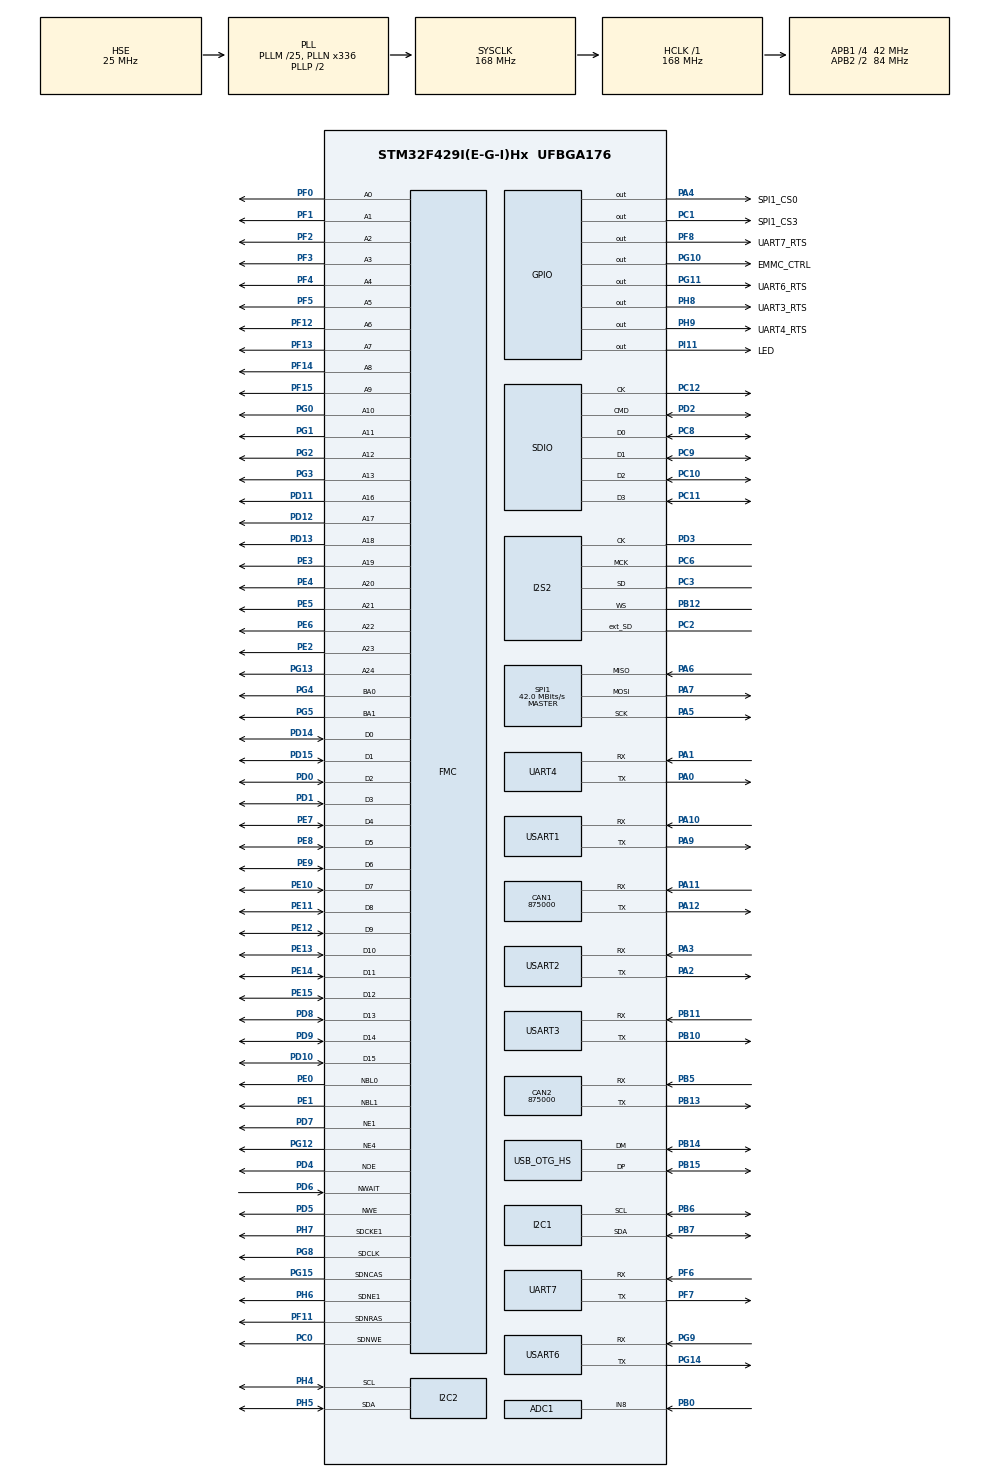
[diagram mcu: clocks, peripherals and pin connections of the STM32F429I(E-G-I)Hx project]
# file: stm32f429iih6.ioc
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ADC1.Channel-0\#ChannelRegularConversion=ADC_CHANNEL_TEMPSENSOR
ADC1.NbrOfConversionFlag=1
ADC1.Rank-0\#ChannelRegularConversion=1
ADC1.SamplingTime-0\#ChannelRegularConversion=ADC_SAMPLETIME_3CYCLES
ADC1.ScanConvMode=DISABLE
ADC1.master=1
CAN1.CalculateBaudRate=875000
CAN1.CalculateTimeBit=1142
CAN1.CalculateTimeQuantum=380.95238095238096
CAN2.CalculateBaudRate=875000
CAN2.CalculateTimeBit=1142
CAN2.CalculateTimeQuantum=380.95238095238096
DMA2D.ColorMode=DMA2D_OUTPUT_RGB565
I2S2.ErrorAudioFreq=0.0 %
I2S2.FullDuplexMode=I2S_FULLDUPLEXMODE_ENABLE
I2S2.Instance=SPI$Index
I2S2.RealAudioFreq=8.0 KHz
I2S2.VirtualMode=I2S_MODE_MASTER
Mcu.Family=STM32F4
Mcu.Name=STM32F429I(E-G-I)Hx
Mcu.Package=UFBGA176
NVIC.PriorityGroup=NVIC_PRIORITYGROUP_4
PA0/WKUP.Mode=Asynchronous
PA0/WKUP.Signal=UART4_TX
PA1.Mode=Asynchronous
PA1.Signal=UART4_RX
PA10.Mode=Asynchronous
PA10.Signal=USART1_RX
PA11.Mode=CAN_Activate
PA11.Signal=CAN1_RX
PA12.Mode=CAN_Activate
PA12.Signal=CAN1_TX
PA13.Mode=Serial_Wire
PA13.Signal=SYS_JTMS-SWDIO
PA14.Mode=Serial_Wire
PA14.Signal=SYS_JTCK-SWCLK
PA2.Mode=Asynchronous
PA2.Signal=USART2_TX
PA3.Mode=Asynchronous
PA3.Signal=USART2_RX
PA4.GPIO_Label=SPI1_CS0
PA4.GPIO_Speed=GPIO_SPEED_FREQ_VERY_HIGH
PA4.Signal=GPIO_Output
PA5.Mode=Full_Duplex_Master
PA5.Signal=SPI1_SCK
PA6.Mode=Full_Duplex_Master
PA6.Signal=SPI1_MISO
PA7.Mode=Full_Duplex_Master
PA7.Signal=SPI1_MOSI
PA9.Mode=Asynchronous
PA9.Signal=USART1_TX
PB0.Signal=ADCx_IN8
PB10.Mode=Asynchronous
PB10.Signal=USART3_TX
PB11.Mode=Asynchronous
PB11.Signal=USART3_RX
PB12.GPIO_Speed=GPIO_SPEED_FREQ_VERY_HIGH
PB12.Mode=Full_Duplex_Master
PB12.Signal=I2S2_WS
PB13.Mode=CAN_Activate
PB13.Signal=CAN2_TX
PB14.Mode=Host_FS
PB14.Signal=USB_OTG_HS_DM
PB15.Mode=Host_FS
PB15.Signal=USB_OTG_HS_DP
PB5.Mode=CAN_Activate
PB5.Signal=CAN2_RX
PB6.GPIO_Pu=GPIO_PULLUP
PB6.Mode=I2C
PB6.Signal=I2C1_SCL
PB7.GPIO_Pu=GPIO_PULLUP
PB7.Mode=I2C
PB7.Signal=I2C1_SDA
PC0.Signal=FMC_SDNWE
PC1.GPIO_Label=SPI1_CS3
PC1.GPIO_Speed=GPIO_SPEED_FREQ_VERY_HIGH
PC1.Signal=GPIO_Output
PC10.GPIO_PuPd=GPIO_PULLUP
PC10.Mode=mmc_4_bits_Wide_bus
PC10.Signal=SDIO_D2
PC11.GPIO_PuPd=GPIO_PULLUP
PC11.Mode=mmc_4_bits_Wide_bus
PC11.Signal=SDIO_D3
PC12.Mode=mmc_4_bits_Wide_bus
PC12.Signal=SDIO_CK
PC2.GPIO_Speed=GPIO_SPEED_FREQ_VERY_HIGH
PC2.Mode=Full_Duplex_Master
PC2.Signal=I2S2_ext_SD
PC3.GPIO_Speed=GPIO_SPEED_FREQ_VERY_HIGH
PC3.Mode=Full_Duplex_Master
PC3.Signal=I2S2_SD
PC6.GPIO_Speed=GPIO_SPEED_FREQ_VERY_HIGH
PC6.Mode=Master_Clock_Activated
PC6.Signal=I2S2_MCK
PC8.GPIO_PuPd=GPIO_PULLUP
PC8.Mode=mmc_4_bits_Wide_bus
PC8.Signal=SDIO_D0
PC9.GPIO_PuPd=GPIO_PULLUP
PC9.Mode=mmc_4_bits_Wide_bus
PC9.Signal=SDIO_D1
PD0.Signal=FMC_D2_DA2
PD1.Signal=FMC_D3_DA3
PD10.Signal=FMC_D15_DA15
PD11.Signal=FMC_A16_CLE
PD12.Signal=FMC_A17_ALE
PD13.Signal=FMC_A18
PD14.Signal=FMC_D0_DA0
PD15.Signal=FMC_D1_DA1
PD2.Mode=mmc_4_bits_Wide_bus
PD2.Signal=SDIO_CMD
PD3.GPIO_Speed=GPIO_SPEED_FREQ_VERY_HIGH
PD3.Mode=Full_Duplex_Master
PD3.Signal=I2S2_CK
PD4.Signal=FMC_NOE
PD5.Signal=FMC_NWE
PD6.Signal=FMC_NWAIT
PD7.Mode=NorPsramChipSelect1_1
PD7.Signal=FMC_NE1
PD8.Signal=FMC_D13_DA13
PD9.Signal=FMC_D14_DA14
PE0.Signal=FMC_NBL0
PE1.Signal=FMC_NBL1
PE10.Signal=FMC_D7_DA7
PE11.Signal=FMC_D8_DA8
PE12.Signal=FMC_D9_DA9
PE13.Signal=FMC_D10_DA10
PE14.Signal=FMC_D11_DA11
PE15.Signal=FMC_D12_DA12
PE2.Signal=FMC_A23
PE3.Signal=FMC_A19
PE4.Signal=FMC_A20
PE5.Signal=FMC_A21
PE6.Signal=FMC_A22
PE7.Signal=FMC_D4_DA4
PE8.Signal=FMC_D5_DA5
PE9.Signal=FMC_D6_DA6
PF0.Signal=FMC_A0
PF1.Signal=FMC_A1
PF11.Signal=FMC_SDNRAS
PF12.Signal=FMC_A6
PF13.Signal=FMC_A7
PF14.Signal=FMC_A8
PF15.Signal=FMC_A9
PF2.Signal=FMC_A2
PF3.Signal=FMC_A3
PF4.Signal=FMC_A4
PF5.Signal=FMC_A5
PF6.Mode=Asynchronous
PF6.Signal=UART7_RX
PF7.Mode=Asynchronous
PF7.Signal=UART7_TX
PF8.GPIO_Label=UART7_RTS
PF8.GPIO_Speed=GPIO_SPEED_FREQ_VERY_HIGH
PF8.Signal=GPIO_Output
PG0.Signal=FMC_A10
PG1.Signal=FMC_A11
PG10.GPIO_Label=EMMC_CTRL
PG10.GPIO_Speed=GPIO_SPEED_FREQ_VERY_HIGH
PG10.Signal=GPIO_Output
PG11.GPIO_Label=UART6_RTS
PG11.GPIO_Speed=GPIO_SPEED_FREQ_VERY_HIGH
PG11.Signal=GPIO_Output
PG12.Mode=NorPsramChipSelect4_4
PG12.Signal=FMC_NE4
PG13.Signal=FMC_A24
PG14.Mode=Asynchronous
PG14.Signal=USART6_TX
PG15.Signal=FMC_SDNCAS
PG2.Signal=FMC_A12
PG3.Signal=FMC_A13
PG4.Signal=FMC_A14_BA0
PG5.Signal=FMC_A15_BA1
PG8.Signal=FMC_SDCLK
PG9.Mode=Asynchronous
PG9.Signal=USART6_RX
PH0/OSC_IN.Mode=HSE-External-Oscillator
PH0/OSC_IN.Signal=RCC_OSC_IN
PH1/OSC_OUT.Mode=HSE-External-Oscillator
PH1/OSC_OUT.Signal=RCC_OSC_OUT
PH4.GPIO_Pu=GPIO_PULLUP
PH4.Mode=I2C
PH4.Signal=I2C2_SCL
PH5.GPIO_Pu=GPIO_PULLUP
PH5.Mode=I2C
PH5.Signal=I2C2_SDA
PH6.Mode=SdramChipSelect2_2
PH6.Signal=FMC_SDNE1
PH7.Mode=SdramChipSelect2_2
PH7.Signal=FMC_SDCKE1
PH8.GPIO_Label=UART3_RTS
PH8.GPIO_Speed=GPIO_SPEED_FREQ_VERY_HIGH
PH8.Signal=GPIO_Output
PH9.GPIO_Label=UART4_RTS
PH9.GPIO_Speed=GPIO_SPEED_FREQ_VERY_HIGH
PH9.Signal=GPIO_Output
PI11.GPIO_Label=LED
PI11.GPIO_Speed=GPIO_SPEED_FREQ_VERY_HIGH
PI11.Signal=GPIO_Output
ProjectManager.HeapSize=0x200
ProjectManager.StackSize=0x400
ProjectManager.TargetToolchain=Makefile
RCC.48MHZClocksFreq_Value=48000000
RCC.AHBFreq_Value=168000000
RCC.APB1CLKDivider=RCC_HCLK_DIV4
RCC.APB1Freq_Value=42000000
RCC.APB1TimFreq_Value=84000000
RCC.APB2CLKDivider=RCC_HCLK_DIV2
RCC.APB2Freq_Value=84000000
RCC.APB2TimFreq_Value=168000000
RCC.CortexFreq_Value=168000000
RCC.HCLKFreq_Value=168000000
RCC.HSE_VALUE=25000000
RCC.HSI_VALUE=16000000
RCC.LSE_VALUE=32768
RCC.PLLI2SN=256
RCC.PLLI2SR=5
RCC.PLLM=25
RCC.PLLN=336
RCC.PLLQ=7
RCC.PLLSAIDivR=RCC_PLLSAIDIVR_8
RCC.PLLSAIN=432
RCC.PLLSAIR=4
RCC.RCC_RTC_Clock_Source=RCC_RTCCLKSOURCE_LSI
RCC.RCC_RTC_Clock_SourceVirtual=RCC_RTCCLKSOURCE_LSE
RCC.SYSCLKFreq_VALUE=168000000
RCC.SYSCLKSource=RCC_SYSCLKSOURCE_PLLCLK
RCC.VCOOutputFreq_Value=336000000
SH.ADCx_IN8.0=ADC1_IN8,IN8
SH.FMC_A0.0=FMC_A0,13b-sda2
SH.FMC_A0.1=FMC_A0,25b-a1
SH.FMC_A0.2=FMC_A0,25b-a4
SH.FMC_A1.0=FMC_A1,13b-sda2
SH.FMC_A1.1=FMC_A1,25b-a1
SH.FMC_A1.2=FMC_A1,25b-a4
SH.FMC_A10.0=FMC_A10,13b-sda2
SH.FMC_A10.1=FMC_A10,25b-a1
SH.FMC_A10.2=FMC_A10,25b-a4
SH.FMC_A11.0=FMC_A11,13b-sda2
SH.FMC_A11.1=FMC_A11,25b-a1
SH.FMC_A11.2=FMC_A11,25b-a4
SH.FMC_A12.0=FMC_A12,13b-sda2
SH.FMC_A12.1=FMC_A12,25b-a1
SH.FMC_A12.2=FMC_A12,25b-a4
SH.FMC_A13.0=FMC_A13,25b-a1
SH.FMC_A13.1=FMC_A13,25b-a4
SH.FMC_A14_BA0.0=FMC_BA0,FourSdramBanks2
SH.FMC_A14_BA0.1=FMC_A14,25b-a1
SH.FMC_A14_BA0.2=FMC_A14,25b-a4
SH.FMC_A15_BA1.0=FMC_BA1,FourSdramBanks2
SH.FMC_A15_BA1.1=FMC_A15,25b-a1
SH.FMC_A15_BA1.2=FMC_A15,25b-a4
SH.FMC_A16_CLE.0=FMC_A16,25b-a1
SH.FMC_A16_CLE.1=FMC_A16,25b-a4
SH.FMC_A17_ALE.0=FMC_A17,25b-a1
SH.FMC_A17_ALE.1=FMC_A17,25b-a4
SH.FMC_A18.0=FMC_A18,25b-a1
SH.FMC_A18.1=FMC_A18,25b-a4
SH.FMC_A19.0=FMC_A19,25b-a1
SH.FMC_A19.1=FMC_A19,25b-a4
SH.FMC_A2.0=FMC_A2,13b-sda2
SH.FMC_A2.1=FMC_A2,25b-a1
SH.FMC_A2.2=FMC_A2,25b-a4
SH.FMC_A20.0=FMC_A20,25b-a1
SH.FMC_A20.1=FMC_A20,25b-a4
SH.FMC_A21.0=FMC_A21,25b-a1
SH.FMC_A21.1=FMC_A21,25b-a4
SH.FMC_A22.0=FMC_A22,25b-a1
SH.FMC_A22.1=FMC_A22,25b-a4
SH.FMC_A23.0=FMC_A23,25b-a1
SH.FMC_A23.1=FMC_A23,25b-a4
SH.FMC_A24.0=FMC_A24,25b-a1
SH.FMC_A24.1=FMC_A24,25b-a4
SH.FMC_A3.0=FMC_A3,13b-sda2
SH.FMC_A3.1=FMC_A3,25b-a1
SH.FMC_A3.2=FMC_A3,25b-a4
SH.FMC_A4.0=FMC_A4,13b-sda2
SH.FMC_A4.1=FMC_A4,25b-a1
SH.FMC_A4.2=FMC_A4,25b-a4
SH.FMC_A5.0=FMC_A5,13b-sda2
SH.FMC_A5.1=FMC_A5,25b-a1
SH.FMC_A5.2=FMC_A5,25b-a4
SH.FMC_A6.0=FMC_A6,13b-sda2
SH.FMC_A6.1=FMC_A6,25b-a1
SH.FMC_A6.2=FMC_A6,25b-a4
SH.FMC_A7.0=FMC_A7,13b-sda2
SH.FMC_A7.1=FMC_A7,25b-a1
SH.FMC_A7.2=FMC_A7,25b-a4
SH.FMC_A8.0=FMC_A8,13b-sda2
SH.FMC_A8.1=FMC_A8,25b-a1
SH.FMC_A8.2=FMC_A8,25b-a4
SH.FMC_A9.0=FMC_A9,13b-sda2
SH.FMC_A9.1=FMC_A9,25b-a1
SH.FMC_A9.2=FMC_A9,25b-a4
SH.FMC_D0_DA0.0=FMC_D0,sd-16b-d2
SH.FMC_D0_DA0.1=FMC_D0,16b-d1
SH.FMC_D0_DA0.2=FMC_D0,16b-d4
SH.FMC_D10_DA10.0=FMC_D10,sd-16b-d2
SH.FMC_D10_DA10.1=FMC_D10,16b-d1
SH.FMC_D10_DA10.2=FMC_D10,16b-d4
SH.FMC_D11_DA11.0=FMC_D11,sd-16b-d2
SH.FMC_D11_DA11.1=FMC_D11,16b-d1
SH.FMC_D11_DA11.2=FMC_D11,16b-d4
SH.FMC_D12_DA12.0=FMC_D12,sd-16b-d2
SH.FMC_D12_DA12.1=FMC_D12,16b-d1
SH.FMC_D12_DA12.2=FMC_D12,16b-d4
SH.FMC_D13_DA13.0=FMC_D13,sd-16b-d2
SH.FMC_D13_DA13.1=FMC_D13,16b-d1
SH.FMC_D13_DA13.2=FMC_D13,16b-d4
SH.FMC_D14_DA14.0=FMC_D14,sd-16b-d2
SH.FMC_D14_DA14.1=FMC_D14,16b-d1
SH.FMC_D14_DA14.2=FMC_D14,16b-d4
SH.FMC_D15_DA15.0=FMC_D15,sd-16b-d2
SH.FMC_D15_DA15.1=FMC_D15,16b-d1
SH.FMC_D15_DA15.2=FMC_D15,16b-d4
SH.FMC_D1_DA1.0=FMC_D1,sd-16b-d2
SH.FMC_D1_DA1.1=FMC_D1,16b-d1
SH.FMC_D1_DA1.2=FMC_D1,16b-d4
SH.FMC_D2_DA2.0=FMC_D2,sd-16b-d2
SH.FMC_D2_DA2.1=FMC_D2,16b-d1
SH.FMC_D2_DA2.2=FMC_D2,16b-d4
SH.FMC_D3_DA3.0=FMC_D3,sd-16b-d2
SH.FMC_D3_DA3.1=FMC_D3,16b-d1
SH.FMC_D3_DA3.2=FMC_D3,16b-d4
SH.FMC_D4_DA4.0=FMC_D4,sd-16b-d2
SH.FMC_D4_DA4.1=FMC_D4,16b-d1
SH.FMC_D4_DA4.2=FMC_D4,16b-d4
SH.FMC_D5_DA5.0=FMC_D5,sd-16b-d2
SH.FMC_D5_DA5.1=FMC_D5,16b-d1
SH.FMC_D5_DA5.2=FMC_D5,16b-d4
SH.FMC_D6_DA6.0=FMC_D6,sd-16b-d2
SH.FMC_D6_DA6.1=FMC_D6,16b-d1
SH.FMC_D6_DA6.2=FMC_D6,16b-d4
SH.FMC_D7_DA7.0=FMC_D7,sd-16b-d2
SH.FMC_D7_DA7.1=FMC_D7,16b-d1
SH.FMC_D7_DA7.2=FMC_D7,16b-d4
SH.FMC_D8_DA8.0=FMC_D8,sd-16b-d2
SH.FMC_D8_DA8.1=FMC_D8,16b-d1
SH.FMC_D8_DA8.2=FMC_D8,16b-d4
SH.FMC_D9_DA9.0=FMC_D9,sd-16b-d2
SH.FMC_D9_DA9.1=FMC_D9,16b-d1
SH.FMC_D9_DA9.2=FMC_D9,16b-d4
SH.FMC_NBL0.0=FMC_NBL0,Sd2ByteEnable2
SH.FMC_NBL0.1=FMC_NBL0,2ByteEnable1
SH.FMC_NBL1.0=FMC_NBL1,Sd2ByteEnable2
SH.FMC_NBL1.1=FMC_NBL1,2ByteEnable1
SH.FMC_NOE.0=FMC_NOE,Sram1
SH.FMC_NOE.1=FMC_NOE,NorFlash4
SH.FMC_NWAIT.0=FMC_NWAIT,AsynchronousWait1
SH.FMC_NWAIT.1=FMC_NWAIT,AsynchronousWait4
SH.FMC_NWE.0=FMC_NWE,Sram1
SH.FMC_NWE.1=FMC_NWE,NorFlash4
SH.FMC_SDCLK.0=FMC_SDCLK,13b-sda2
SH.FMC_SDNCAS.0=FMC_SDNCAS,13b-sda2
SH.FMC_SDNRAS.0=FMC_SDNRAS,13b-sda2
SH.FMC_SDNWE.0=FMC_SDNWE,13b-sda2
SPI1.CalculateBaudRate=42.0 MBits/s
SPI1.Direction=SPI_DIRECTION_2LINES
SPI1.Mode=SPI_MODE_MASTER
SPI1.VirtualType=VM_MASTER
UART4.VirtualMode=Asynchronous
UART7.VirtualMode=Asynchronous
USART1.VirtualMode=VM_ASYNC
USART2.VirtualMode=VM_ASYNC
USART3.VirtualMode=VM_ASYNC
USART6.VirtualMode=VM_ASYNC
USB_OTG_HS.VirtualMode-Host_FS=Host_FS
VP_ADC1_TempSens_Input.Mode=IN-TempSens
VP_CRC_VS_CRC.Mode=CRC_Activate
VP_DMA2D_VS_DMA2D.Mode=DMA2D_Activate
VP_IWDG_VS_IWDG.Mode=IWDG_Activate
VP_RNG_VS_RNG.Mode=RNG_Activate
VP_RTC_VS_RTC_Activate.Mode=RTC_Enabled
VP_RTC_VS_RTC_Calendar.Mode=RTC_Calendar
board=custom

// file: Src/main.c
/* USER CODE BEGIN Header */
/**
  ******************************************************************************
  * @file           : main.c
  * @brief          : Main program body
  ******************************************************************************
  * @attention
  *
  * Copyright (c) 2022 STMicroelectronics.
  * All rights reserved.
  *
  * This software is licensed under terms that can be found in the LICENSE file
  * in the root directory of this software component.
  * If no LICENSE file comes with this software, it is provided AS-IS.
  *
  ******************************************************************************
  */
/* USER CODE END Header */
#include "main.h"

/* USER CODE BEGIN Includes */
#define DBG_TAG "cube"
#define DBG_LVL DBG_LOG
#include <rtdbg.h>
/* USER CODE END Includes */

ADC_HandleTypeDef hadc1;

CAN_HandleTypeDef hcan1;
CAN_HandleTypeDef hcan2;

CRC_HandleTypeDef hcrc;

DMA2D_HandleTypeDef hdma2d;

I2C_HandleTypeDef hi2c1;
I2C_HandleTypeDef hi2c2;

I2S_HandleTypeDef hi2s2;

IWDG_HandleTypeDef hiwdg;

RNG_HandleTypeDef hrng;

RTC_HandleTypeDef hrtc;

MMC_HandleTypeDef hmmc;

SPI_HandleTypeDef hspi1;

UART_HandleTypeDef huart4;
UART_HandleTypeDef huart7;
UART_HandleTypeDef huart1;
UART_HandleTypeDef huart2;
UART_HandleTypeDef huart3;
UART_HandleTypeDef huart6;

HCD_HandleTypeDef hhcd_USB_OTG_HS;

SRAM_HandleTypeDef hsram1;
NOR_HandleTypeDef hnor4;
SDRAM_HandleTypeDef hsdram2;

void SystemClock_Config(void);
static void MX_GPIO_Init(void);
static void MX_CRC_Init(void);
static void MX_RTC_Init(void);
static void MX_USART3_UART_Init(void);
static void MX_IWDG_Init(void);
static void MX_FMC_Init(void);
static void MX_SPI1_Init(void);
static void MX_SDIO_MMC_Init(void);
static void MX_CAN1_Init(void);
static void MX_CAN2_Init(void);
static void MX_USB_OTG_HS_HCD_Init(void);
static void MX_I2C1_Init(void);
static void MX_I2C2_Init(void);
static void MX_UART4_Init(void);
static void MX_I2S2_Init(void);
static void MX_ADC1_Init(void);
static void MX_DMA2D_Init(void);
static void MX_RNG_Init(void);
static void MX_USART1_UART_Init(void);
static void MX_USART6_UART_Init(void);
static void MX_UART7_Init(void);
static void MX_USART2_UART_Init(void);

/* USER CODE BEGIN 0 */
__weak
/* USER CODE END 0 */

int main(void)
{

  /* MCU Configuration--------------------------------------------------------*/

  /* Reset of all peripherals, Initializes the Flash interface and the Systick. */
  HAL_Init();

  /* Configure the system clock */
  SystemClock_Config();

  /* Initialize all configured peripherals */
  MX_GPIO_Init();
  MX_CRC_Init();
  MX_RTC_Init();
  MX_USART3_UART_Init();
  MX_IWDG_Init();
  MX_FMC_Init();
  MX_SPI1_Init();
  MX_SDIO_MMC_Init();
  MX_CAN1_Init();
  MX_CAN2_Init();
  MX_USB_OTG_HS_HCD_Init();
  MX_I2C1_Init();
  MX_I2C2_Init();
  MX_UART4_Init();
  MX_I2S2_Init();
  MX_ADC1_Init();
  MX_DMA2D_Init();
  MX_RNG_Init();
  MX_USART1_UART_Init();
  MX_USART6_UART_Init();
  MX_UART7_Init();
  MX_USART2_UART_Init();

  /* Infinite loop */
  while (1)
  {

  }
}

void SystemClock_Config(void)
{
  RCC_OscInitTypeDef RCC_OscInitStruct = {0};
  RCC_ClkInitTypeDef RCC_ClkInitStruct = {0};

  /** Configure the main internal regulator output voltage
  */
  __HAL_RCC_PWR_CLK_ENABLE();
  __HAL_PWR_VOLTAGESCALING_CONFIG(PWR_REGULATOR_VOLTAGE_SCALE1);

  /** Initializes the RCC Oscillators according to the specified parameters
  * in the RCC_OscInitTypeDef structure.
  */
  RCC_OscInitStruct.OscillatorType = RCC_OSCILLATORTYPE_LSI|RCC_OSCILLATORTYPE_HSE;
  RCC_OscInitStruct.HSEState = RCC_HSE_ON;
  RCC_OscInitStruct.LSIState = RCC_LSI_ON;
  RCC_OscInitStruct.PLL.PLLState = RCC_PLL_ON;
  RCC_OscInitStruct.PLL.PLLSource = RCC_PLLSOURCE_HSE;
  RCC_OscInitStruct.PLL.PLLM = 25;
  RCC_OscInitStruct.PLL.PLLN = 336;
  RCC_OscInitStruct.PLL.PLLP = RCC_PLLP_DIV2;
  RCC_OscInitStruct.PLL.PLLQ = 7;
  if (HAL_RCC_OscConfig(&RCC_OscInitStruct) != HAL_OK)
  {
    Error_Handler();
  }

  /** Initializes the CPU, AHB and APB buses clocks
  */
  RCC_ClkInitStruct.ClockType = RCC_CLOCKTYPE_HCLK|RCC_CLOCKTYPE_SYSCLK
                              |RCC_CLOCKTYPE_PCLK1|RCC_CLOCKTYPE_PCLK2;
  RCC_ClkInitStruct.SYSCLKSource = RCC_SYSCLKSOURCE_PLLCLK;
  RCC_ClkInitStruct.AHBCLKDivider = RCC_SYSCLK_DIV1;
  RCC_ClkInitStruct.APB1CLKDivider = RCC_HCLK_DIV4;
  RCC_ClkInitStruct.APB2CLKDivider = RCC_HCLK_DIV2;

  if (HAL_RCC_ClockConfig(&RCC_ClkInitStruct, FLASH_LATENCY_5) != HAL_OK)
  {
    Error_Handler();
  }
}

static void MX_ADC1_Init(void)
{

  ADC_ChannelConfTypeDef sConfig = {0};

  /** Configure the global features of the ADC (Clock, Resolution, Data Alignment and number of conversion)
  */
  hadc1.Instance = ADC1;
  hadc1.Init.ClockPrescaler = ADC_CLOCK_SYNC_PCLK_DIV4;
  hadc1.Init.Resolution = ADC_RESOLUTION_12B;
  hadc1.Init.ScanConvMode = DISABLE;
  hadc1.Init.ContinuousConvMode = DISABLE;
  hadc1.Init.DiscontinuousConvMode = DISABLE;
  hadc1.Init.ExternalTrigConvEdge = ADC_EXTERNALTRIGCONVEDGE_NONE;
  hadc1.Init.ExternalTrigConv = ADC_SOFTWARE_START;
  hadc1.Init.DataAlign = ADC_DATAALIGN_RIGHT;
  hadc1.Init.NbrOfConversion = 1;
  hadc1.Init.DMAContinuousRequests = DISABLE;
  hadc1.Init.EOCSelection = ADC_EOC_SINGLE_CONV;
  if (HAL_ADC_Init(&hadc1) != HAL_OK)
  {
    Error_Handler();
  }

  /** Configure for the selected ADC regular channel its corresponding rank in the sequencer and its sample time.
  */
  sConfig.Channel = ADC_CHANNEL_TEMPSENSOR;
  sConfig.Rank = 1;
  sConfig.SamplingTime = ADC_SAMPLETIME_3CYCLES;
  if (HAL_ADC_ConfigChannel(&hadc1, &sConfig) != HAL_OK)
  {
    Error_Handler();
  }

}

static void MX_CAN1_Init(void)
{

  hcan1.Instance = CAN1;
  hcan1.Init.Prescaler = 16;
  hcan1.Init.Mode = CAN_MODE_NORMAL;
  hcan1.Init.SyncJumpWidth = CAN_SJW_1TQ;
  hcan1.Init.TimeSeg1 = CAN_BS1_1TQ;
  hcan1.Init.TimeSeg2 = CAN_BS2_1TQ;
  hcan1.Init.TimeTriggeredMode = DISABLE;
  hcan1.Init.AutoBusOff = DISABLE;
  hcan1.Init.AutoWakeUp = DISABLE;
  hcan1.Init.AutoRetransmission = DISABLE;
  hcan1.Init.ReceiveFifoLocked = DISABLE;
  hcan1.Init.TransmitFifoPriority = DISABLE;
  if (HAL_CAN_Init(&hcan1) != HAL_OK)
  {
    Error_Handler();
  }

}

static void MX_CAN2_Init(void)
{

  hcan2.Instance = CAN2;
  hcan2.Init.Prescaler = 16;
  hcan2.Init.Mode = CAN_MODE_NORMAL;
  hcan2.Init.SyncJumpWidth = CAN_SJW_1TQ;
  hcan2.Init.TimeSeg1 = CAN_BS1_1TQ;
  hcan2.Init.TimeSeg2 = CAN_BS2_1TQ;
  hcan2.Init.TimeTriggeredMode = DISABLE;
  hcan2.Init.AutoBusOff = DISABLE;
  hcan2.Init.AutoWakeUp = DISABLE;
  hcan2.Init.AutoRetransmission = DISABLE;
  hcan2.Init.ReceiveFifoLocked = DISABLE;
  hcan2.Init.TransmitFifoPriority = DISABLE;
  if (HAL_CAN_Init(&hcan2) != HAL_OK)
  {
    Error_Handler();
  }

}

static void MX_CRC_Init(void)
{

  hcrc.Instance = CRC;
  if (HAL_CRC_Init(&hcrc) != HAL_OK)
  {
    Error_Handler();
  }

}

static void MX_DMA2D_Init(void)
{

  hdma2d.Instance = DMA2D;
  hdma2d.Init.Mode = DMA2D_M2M;
  hdma2d.Init.ColorMode = DMA2D_OUTPUT_RGB565;
  hdma2d.Init.OutputOffset = 0;
  hdma2d.LayerCfg[1].InputOffset = 0;
  hdma2d.LayerCfg[1].InputColorMode = DMA2D_INPUT_RGB565;
  hdma2d.LayerCfg[1].AlphaMode = DMA2D_NO_MODIF_ALPHA;
  hdma2d.LayerCfg[1].InputAlpha = 0;
  if (HAL_DMA2D_Init(&hdma2d) != HAL_OK)
  {
    Error_Handler();
  }
  if (HAL_DMA2D_ConfigLayer(&hdma2d, 1) != HAL_OK)
  {
    Error_Handler();
  }

}

static void MX_I2C1_Init(void)
{

  hi2c1.Instance = I2C1;
  hi2c1.Init.ClockSpeed = 100000;
  hi2c1.Init.DutyCycle = I2C_DUTYCYCLE_2;
  hi2c1.Init.OwnAddress1 = 0;
  hi2c1.Init.AddressingMode = I2C_ADDRESSINGMODE_7BIT;
  hi2c1.Init.DualAddressMode = I2C_DUALADDRESS_DISABLE;
  hi2c1.Init.OwnAddress2 = 0;
  hi2c1.Init.GeneralCallMode = I2C_GENERALCALL_DISABLE;
  hi2c1.Init.NoStretchMode = I2C_NOSTRETCH_DISABLE;
  if (HAL_I2C_Init(&hi2c1) != HAL_OK)
  {
    Error_Handler();
  }

  /** Configure Analogue filter
  */
  if (HAL_I2CEx_ConfigAnalogFilter(&hi2c1, I2C_ANALOGFILTER_ENABLE) != HAL_OK)
  {
    Error_Handler();
  }

  /** Configure Digital filter
  */
  if (HAL_I2CEx_ConfigDigitalFilter(&hi2c1, 0) != HAL_OK)
  {
    Error_Handler();
  }

}

static void MX_I2C2_Init(void)
{

  hi2c2.Instance = I2C2;
  hi2c2.Init.ClockSpeed = 100000;
  hi2c2.Init.DutyCycle = I2C_DUTYCYCLE_2;
  hi2c2.Init.OwnAddress1 = 0;
  hi2c2.Init.AddressingMode = I2C_ADDRESSINGMODE_7BIT;
  hi2c2.Init.DualAddressMode = I2C_DUALADDRESS_DISABLE;
  hi2c2.Init.OwnAddress2 = 0;
  hi2c2.Init.GeneralCallMode = I2C_GENERALCALL_DISABLE;
  hi2c2.Init.NoStretchMode = I2C_NOSTRETCH_DISABLE;
  if (HAL_I2C_Init(&hi2c2) != HAL_OK)
  {
    Error_Handler();
  }

  /** Configure Analogue filter
  */
  if (HAL_I2CEx_ConfigAnalogFilter(&hi2c2, I2C_ANALOGFILTER_ENABLE) != HAL_OK)
  {
    Error_Handler();
  }

  /** Configure Digital filter
  */
  if (HAL_I2CEx_ConfigDigitalFilter(&hi2c2, 0) != HAL_OK)
  {
    Error_Handler();
  }

}

static void MX_I2S2_Init(void)
{

  hi2s2.Instance = SPI2;
  hi2s2.Init.Mode = I2S_MODE_MASTER_TX;
  hi2s2.Init.Standard = I2S_STANDARD_PHILIPS;
  hi2s2.Init.DataFormat = I2S_DATAFORMAT_16B;
  hi2s2.Init.MCLKOutput = I2S_MCLKOUTPUT_ENABLE;
  hi2s2.Init.AudioFreq = I2S_AUDIOFREQ_8K;
  hi2s2.Init.CPOL = I2S_CPOL_LOW;
  hi2s2.Init.ClockSource = I2S_CLOCK_PLL;
  hi2s2.Init.FullDuplexMode = I2S_FULLDUPLEXMODE_ENABLE;
  if (HAL_I2S_Init(&hi2s2) != HAL_OK)
  {
    Error_Handler();
  }

}

static void MX_IWDG_Init(void)
{

  hiwdg.Instance = IWDG;
  hiwdg.Init.Prescaler = IWDG_PRESCALER_4;
  hiwdg.Init.Reload = 4095;
  if (HAL_IWDG_Init(&hiwdg) != HAL_OK)
  {
    Error_Handler();
  }

}

static void MX_RNG_Init(void)
{

  hrng.Instance = RNG;
  if (HAL_RNG_Init(&hrng) != HAL_OK)
  {
    Error_Handler();
  }

}

static void MX_RTC_Init(void)
{

  RTC_TimeTypeDef sTime = {0};
  RTC_DateTypeDef sDate = {0};

  /** Initialize RTC Only
  */
  hrtc.Instance = RTC;
  hrtc.Init.HourFormat = RTC_HOURFORMAT_24;
  hrtc.Init.AsynchPrediv = 127;
  hrtc.Init.SynchPrediv = 255;
  hrtc.Init.OutPut = RTC_OUTPUT_DISABLE;
  hrtc.Init.OutPutPolarity = RTC_OUTPUT_POLARITY_HIGH;
  hrtc.Init.OutPutType = RTC_OUTPUT_TYPE_OPENDRAIN;
  if (HAL_RTC_Init(&hrtc) != HAL_OK)
  {
    Error_Handler();
  }

  /** Initialize RTC and set the Time and Date
  */
  sTime.Hours = 0x0;
  sTime.Minutes = 0x0;
  sTime.Seconds = 0x0;
  sTime.DayLightSaving = RTC_DAYLIGHTSAVING_NONE;
  sTime.StoreOperation = RTC_STOREOPERATION_RESET;
  if (HAL_RTC_SetTime(&hrtc, &sTime, RTC_FORMAT_BCD) != HAL_OK)
  {
    Error_Handler();
  }
  sDate.WeekDay = RTC_WEEKDAY_MONDAY;
  sDate.Month = RTC_MONTH_JANUARY;
  sDate.Date = 0x1;
  sDate.Year = 0x0;

  if (HAL_RTC_SetDate(&hrtc, &sDate, RTC_FORMAT_BCD) != HAL_OK)
  {
    Error_Handler();
  }

}

static void MX_SDIO_MMC_Init(void)
{

  hmmc.Instance = SDIO;
  hmmc.Init.ClockEdge = SDIO_CLOCK_EDGE_RISING;
  hmmc.Init.ClockBypass = SDIO_CLOCK_BYPASS_DISABLE;
  hmmc.Init.ClockPowerSave = SDIO_CLOCK_POWER_SAVE_DISABLE;
  hmmc.Init.BusWide = SDIO_BUS_WIDE_4B;
  hmmc.Init.HardwareFlowControl = SDIO_HARDWARE_FLOW_CONTROL_DISABLE;
  hmmc.Init.ClockDiv = 0;
  if (HAL_MMC_Init(&hmmc) != HAL_OK)
  {
    Error_Handler();
  }
  if (HAL_MMC_ConfigWideBusOperation(&hmmc, SDIO_BUS_WIDE_4B) != HAL_OK)
  {
    Error_Handler();
  }

}

static void MX_SPI1_Init(void)
{

  /* SPI1 parameter configuration*/
  hspi1.Instance = SPI1;
  hspi1.Init.Mode = SPI_MODE_MASTER;
  hspi1.Init.Direction = SPI_DIRECTION_2LINES;
  hspi1.Init.DataSize = SPI_DATASIZE_8BIT;
  hspi1.Init.CLKPolarity = SPI_POLARITY_LOW;
  hspi1.Init.CLKPhase = SPI_PHASE_1EDGE;
  hspi1.Init.NSS = SPI_NSS_SOFT;
  hspi1.Init.BaudRatePrescaler = SPI_BAUDRATEPRESCALER_2;
  hspi1.Init.FirstBit = SPI_FIRSTBIT_MSB;
  hspi1.Init.TIMode = SPI_TIMODE_DISABLE;
  hspi1.Init.CRCCalculation = SPI_CRCCALCULATION_DISABLE;
  hspi1.Init.CRCPolynomial = 10;
  if (HAL_SPI_Init(&hspi1) != HAL_OK)
  {
    Error_Handler();
  }

}

static void MX_UART4_Init(void)
{

  huart4.Instance = UART4;
  huart4.Init.BaudRate = 115200;
  huart4.Init.WordLength = UART_WORDLENGTH_8B;
  huart4.Init.StopBits = UART_STOPBITS_1;
  huart4.Init.Parity = UART_PARITY_NONE;
  huart4.Init.Mode = UART_MODE_TX_RX;
  huart4.Init.HwFlowCtl = UART_HWCONTROL_NONE;
  huart4.Init.OverSampling = UART_OVERSAMPLING_16;
  if (HAL_UART_Init(&huart4) != HAL_OK)
  {
    Error_Handler();
  }

}

static void MX_UART7_Init(void)
{

  huart7.Instance = UART7;
  huart7.Init.BaudRate = 115200;
  huart7.Init.WordLength = UART_WORDLENGTH_8B;
  huart7.Init.StopBits = UART_STOPBITS_1;
  huart7.Init.Parity = UART_PARITY_NONE;
  huart7.Init.Mode = UART_MODE_TX_RX;
  huart7.Init.HwFlowCtl = UART_HWCONTROL_NONE;
  huart7.Init.OverSampling = UART_OVERSAMPLING_16;
  if (HAL_UART_Init(&huart7) != HAL_OK)
  {
    Error_Handler();
  }

}

static void MX_USART1_UART_Init(void)
{

  huart1.Instance = USART1;
  huart1.Init.BaudRate = 115200;
  huart1.Init.WordLength = UART_WORDLENGTH_8B;
  huart1.Init.StopBits = UART_STOPBITS_1;
  huart1.Init.Parity = UART_PARITY_NONE;
  huart1.Init.Mode = UART_MODE_TX_RX;
  huart1.Init.HwFlowCtl = UART_HWCONTROL_NONE;
  huart1.Init.OverSampling = UART_OVERSAMPLING_16;
  if (HAL_UART_Init(&huart1) != HAL_OK)
  {
    Error_Handler();
  }

}

static void MX_USART2_UART_Init(void)
{

  huart2.Instance = USART2;
  huart2.Init.BaudRate = 115200;
  huart2.Init.WordLength = UART_WORDLENGTH_8B;
  huart2.Init.StopBits = UART_STOPBITS_1;
  huart2.Init.Parity = UART_PARITY_NONE;
  huart2.Init.Mode = UART_MODE_TX_RX;
  huart2.Init.HwFlowCtl = UART_HWCONTROL_NONE;
  huart2.Init.OverSampling = UART_OVERSAMPLING_16;
  if (HAL_UART_Init(&huart2) != HAL_OK)
  {
    Error_Handler();
  }

}

static void MX_USART3_UART_Init(void)
{

  huart3.Instance = USART3;
  huart3.Init.BaudRate = 115200;
  huart3.Init.WordLength = UART_WORDLENGTH_8B;
  huart3.Init.StopBits = UART_STOPBITS_1;
  huart3.Init.Parity = UART_PARITY_NONE;
  huart3.Init.Mode = UART_MODE_TX_RX;
  huart3.Init.HwFlowCtl = UART_HWCONTROL_NONE;
  huart3.Init.OverSampling = UART_OVERSAMPLING_16;
  if (HAL_UART_Init(&huart3) != HAL_OK)
  {
    Error_Handler();
  }

}

static void MX_USART6_UART_Init(void)
{

  huart6.Instance = USART6;
  huart6.Init.BaudRate = 115200;
  huart6.Init.WordLength = UART_WORDLENGTH_8B;
  huart6.Init.StopBits = UART_STOPBITS_1;
  huart6.Init.Parity = UART_PARITY_NONE;
  huart6.Init.Mode = UART_MODE_TX_RX;
  huart6.Init.HwFlowCtl = UART_HWCONTROL_NONE;
  huart6.Init.OverSampling = UART_OVERSAMPLING_16;
  if (HAL_UART_Init(&huart6) != HAL_OK)
  {
    Error_Handler();
  }

}

static void MX_USB_OTG_HS_HCD_Init(void)
{

  hhcd_USB_OTG_HS.Instance = USB_OTG_HS;
  hhcd_USB_OTG_HS.Init.Host_channels = 12;
  hhcd_USB_OTG_HS.Init.speed = HCD_SPEED_FULL;
  hhcd_USB_OTG_HS.Init.dma_enable = DISABLE;
  hhcd_USB_OTG_HS.Init.phy_itface = USB_OTG_EMBEDDED_PHY;
  hhcd_USB_OTG_HS.Init.Sof_enable = DISABLE;
  hhcd_USB_OTG_HS.Init.low_power_enable = DISABLE;
  hhcd_USB_OTG_HS.Init.vbus_sensing_enable = DISABLE;
  hhcd_USB_OTG_HS.Init.use_external_vbus = DISABLE;
  if (HAL_HCD_Init(&hhcd_USB_OTG_HS) != HAL_OK)
  {
    Error_Handler();
  }

}

/* FMC initialization function */
static void MX_FMC_Init(void)
{

  FMC_NORSRAM_TimingTypeDef Timing = {0};
  FMC_SDRAM_TimingTypeDef SdramTiming = {0};

  /** Perform the SRAM1 memory initialization sequence
  */
  hsram1.Instance = FMC_NORSRAM_DEVICE;
  hsram1.Extended = FMC_NORSRAM_EXTENDED_DEVICE;
  /* hsram1.Init */
  hsram1.Init.NSBank = FMC_NORSRAM_BANK1;
  hsram1.Init.DataAddressMux = FMC_DATA_ADDRESS_MUX_DISABLE;
  hsram1.Init.MemoryType = FMC_MEMORY_TYPE_SRAM;
  hsram1.Init.MemoryDataWidth = FMC_NORSRAM_MEM_BUS_WIDTH_16;
  hsram1.Init.BurstAccessMode = FMC_BURST_ACCESS_MODE_DISABLE;
  hsram1.Init.WaitSignalPolarity = FMC_WAIT_SIGNAL_POLARITY_LOW;
  hsram1.Init.WrapMode = FMC_WRAP_MODE_DISABLE;
  hsram1.Init.WaitSignalActive = FMC_WAIT_TIMING_BEFORE_WS;
  hsram1.Init.WriteOperation = FMC_WRITE_OPERATION_DISABLE;
  hsram1.Init.WaitSignal = FMC_WAIT_SIGNAL_DISABLE;
  hsram1.Init.ExtendedMode = FMC_EXTENDED_MODE_DISABLE;
  hsram1.Init.AsynchronousWait = FMC_ASYNCHRONOUS_WAIT_ENABLE;
  hsram1.Init.WriteBurst = FMC_WRITE_BURST_DISABLE;
  hsram1.Init.ContinuousClock = FMC_CONTINUOUS_CLOCK_SYNC_ONLY;
  hsram1.Init.PageSize = FMC_PAGE_SIZE_NONE;
  /* Timing */
  Timing.AddressSetupTime = 15;
  Timing.AddressHoldTime = 15;
  Timing.DataSetupTime = 255;
  Timing.BusTurnAroundDuration = 15;
  Timing.CLKDivision = 16;
  Timing.DataLatency = 17;
  Timing.AccessMode = FMC_ACCESS_MODE_A;
  /* ExtTiming */

  if (HAL_SRAM_Init(&hsram1, &Timing, NULL) != HAL_OK)
  {
    Error_Handler( );
  }

  /** Perform the NOR4 memory initialization sequence
  */
  hnor4.Instance = FMC_NORSRAM_DEVICE;
  hnor4.Extended = FMC_NORSRAM_EXTENDED_DEVICE;
  /* hnor4.Init */
  hnor4.Init.NSBank = FMC_NORSRAM_BANK4;
  hnor4.Init.DataAddressMux = FMC_DATA_ADDRESS_MUX_DISABLE;
  hnor4.Init.MemoryType = FMC_MEMORY_TYPE_NOR;
  hnor4.Init.MemoryDataWidth = FMC_NORSRAM_MEM_BUS_WIDTH_16;
  hnor4.Init.BurstAccessMode = FMC_BURST_ACCESS_MODE_DISABLE;
  hnor4.Init.WaitSignalPolarity = FMC_WAIT_SIGNAL_POLARITY_LOW;
  hnor4.Init.WrapMode = FMC_WRAP_MODE_DISABLE;
  hnor4.Init.WaitSignalActive = FMC_WAIT_TIMING_BEFORE_WS;
  hnor4.Init.WriteOperation = FMC_WRITE_OPERATION_DISABLE;
  hnor4.Init.WaitSignal = FMC_WAIT_SIGNAL_DISABLE;
  hnor4.Init.ExtendedMode = FMC_EXTENDED_MODE_DISABLE;
  hnor4.Init.AsynchronousWait = FMC_ASYNCHRONOUS_WAIT_ENABLE;
  hnor4.Init.WriteBurst = FMC_WRITE_BURST_DISABLE;
  hnor4.Init.ContinuousClock = FMC_CONTINUOUS_CLOCK_SYNC_ONLY;
  hnor4.Init.PageSize = FMC_PAGE_SIZE_NONE;
  /* Timing */
  Timing.AddressSetupTime = 15;
  Timing.AddressHoldTime = 15;
  Timing.DataSetupTime = 255;
  Timing.BusTurnAroundDuration = 15;
  Timing.CLKDivision = 16;
  Timing.DataLatency = 17;
  Timing.AccessMode = FMC_ACCESS_MODE_A;
  /* ExtTiming */

  if (HAL_NOR_Init(&hnor4, &Timing, NULL) != HAL_OK)
  {
    Error_Handler( );
  }

  /** Perform the SDRAM2 memory initialization sequence
  */
  hsdram2.Instance = FMC_SDRAM_DEVICE;
  /* hsdram2.Init */
  hsdram2.Init.SDBank = FMC_SDRAM_BANK2;
  hsdram2.Init.ColumnBitsNumber = FMC_SDRAM_COLUMN_BITS_NUM_8;
  hsdram2.Init.RowBitsNumber = FMC_SDRAM_ROW_BITS_NUM_13;
  hsdram2.Init.MemoryDataWidth = FMC_SDRAM_MEM_BUS_WIDTH_16;
  hsdram2.Init.InternalBankNumber = FMC_SDRAM_INTERN_BANKS_NUM_4;
  hsdram2.Init.CASLatency = FMC_SDRAM_CAS_LATENCY_1;
  hsdram2.Init.WriteProtection = FMC_SDRAM_WRITE_PROTECTION_DISABLE;
  hsdram2.Init.SDClockPeriod = FMC_SDRAM_CLOCK_DISABLE;
  hsdram2.Init.ReadBurst = FMC_SDRAM_RBURST_DISABLE;
  hsdram2.Init.ReadPipeDelay = FMC_SDRAM_RPIPE_DELAY_0;
  /* SdramTiming */
  SdramTiming.LoadToActiveDelay = 16;
  SdramTiming.ExitSelfRefreshDelay = 16;
  SdramTiming.SelfRefreshTime = 16;
  SdramTiming.RowCycleDelay = 16;
  SdramTiming.WriteRecoveryTime = 16;
  SdramTiming.RPDelay = 16;
  SdramTiming.RCDDelay = 16;

  if (HAL_SDRAM_Init(&hsdram2, &SdramTiming) != HAL_OK)
  {
    Error_Handler( );
  }

}

static void MX_GPIO_Init(void)
{
  GPIO_InitTypeDef GPIO_InitStruct = {0};

  /* GPIO Ports Clock Enable */
  __HAL_RCC_GPIOE_CLK_ENABLE();
  __HAL_RCC_GPIOB_CLK_ENABLE();
  __HAL_RCC_GPIOG_CLK_ENABLE();
  __HAL_RCC_GPIOD_CLK_ENABLE();
  __HAL_RCC_GPIOC_CLK_ENABLE();
  __HAL_RCC_GPIOA_CLK_ENABLE();
  __HAL_RCC_GPIOF_CLK_ENABLE();
  __HAL_RCC_GPIOI_CLK_ENABLE();
  __HAL_RCC_GPIOH_CLK_ENABLE();

  /*Configure GPIO pin Output Level */
  HAL_GPIO_WritePin(GPIOG, UART6_RTS_Pin|EMMC_CTRL_Pin, GPIO_PIN_RESET);

  /*Configure GPIO pin Output Level */
  HAL_GPIO_WritePin(LED_GPIO_Port, LED_Pin, GPIO_PIN_RESET);

  /*Configure GPIO pin Output Level */
  HAL_GPIO_WritePin(UART7_RTS_GPIO_Port, UART7_RTS_Pin, GPIO_PIN_RESET);

  /*Configure GPIO pin Output Level */
  HAL_GPIO_WritePin(SPI1_CS3_GPIO_Port, SPI1_CS3_Pin, GPIO_PIN_RESET);

  /*Configure GPIO pin Output Level */
  HAL_GPIO_WritePin(GPIOH, UART3_RTS_Pin|UART4_RTS_Pin, GPIO_PIN_RESET);

  /*Configure GPIO pin Output Level */
  HAL_GPIO_WritePin(SPI1_CS0_GPIO_Port, SPI1_CS0_Pin, GPIO_PIN_RESET);

  /*Configure GPIO pins : UART6_RTS_Pin EMMC_CTRL_Pin */
  GPIO_InitStruct.Pin = UART6_RTS_Pin|EMMC_CTRL_Pin;
  GPIO_InitStruct.Mode = GPIO_MODE_OUTPUT_PP;
  GPIO_InitStruct.Pull = GPIO_NOPULL;
  GPIO_InitStruct.Speed = GPIO_SPEED_FREQ_VERY_HIGH;
  HAL_GPIO_Init(GPIOG, &GPIO_InitStruct);

  /*Configure GPIO pin : LED_Pin */
  GPIO_InitStruct.Pin = LED_Pin;
  GPIO_InitStruct.Mode = GPIO_MODE_OUTPUT_PP;
  GPIO_InitStruct.Pull = GPIO_NOPULL;
  GPIO_InitStruct.Speed = GPIO_SPEED_FREQ_VERY_HIGH;
  HAL_GPIO_Init(LED_GPIO_Port, &GPIO_InitStruct);

  /*Configure GPIO pin : UART7_RTS_Pin */
  GPIO_InitStruct.Pin = UART7_RTS_Pin;
  GPIO_InitStruct.Mode = GPIO_MODE_OUTPUT_PP;
  GPIO_InitStruct.Pull = GPIO_NOPULL;
  GPIO_InitStruct.Speed = GPIO_SPEED_FREQ_VERY_HIGH;
  HAL_GPIO_Init(UART7_RTS_GPIO_Port, &GPIO_InitStruct);

  /*Configure GPIO pin : SPI1_CS3_Pin */
  GPIO_InitStruct.Pin = SPI1_CS3_Pin;
  GPIO_InitStruct.Mode = GPIO_MODE_OUTPUT_PP;
  GPIO_InitStruct.Pull = GPIO_NOPULL;
  GPIO_InitStruct.Speed = GPIO_SPEED_FREQ_VERY_HIGH;
  HAL_GPIO_Init(SPI1_CS3_GPIO_Port, &GPIO_InitStruct);

  /*Configure GPIO pins : UART3_RTS_Pin UART4_RTS_Pin */
  GPIO_InitStruct.Pin = UART3_RTS_Pin|UART4_RTS_Pin;
  GPIO_InitStruct.Mode = GPIO_MODE_OUTPUT_PP;
  GPIO_InitStruct.Pull = GPIO_NOPULL;
  GPIO_InitStruct.Speed = GPIO_SPEED_FREQ_VERY_HIGH;
  HAL_GPIO_Init(GPIOH, &GPIO_InitStruct);

  /*Configure GPIO pin : SPI1_CS0_Pin */
  GPIO_InitStruct.Pin = SPI1_CS0_Pin;
  GPIO_InitStruct.Mode = GPIO_MODE_OUTPUT_PP;
  GPIO_InitStruct.Pull = GPIO_NOPULL;
  GPIO_InitStruct.Speed = GPIO_SPEED_FREQ_VERY_HIGH;
  HAL_GPIO_Init(SPI1_CS0_GPIO_Port, &GPIO_InitStruct);

}

void Error_Handler(void)
{
  /* USER CODE BEGIN Error_Handler_Debug */
  /* User can add his own implementation to report the HAL error return state */
  LOG_E("Error_Handler");
  while (1)
  {
  }
  /* USER CODE END Error_Handler_Debug */
}
